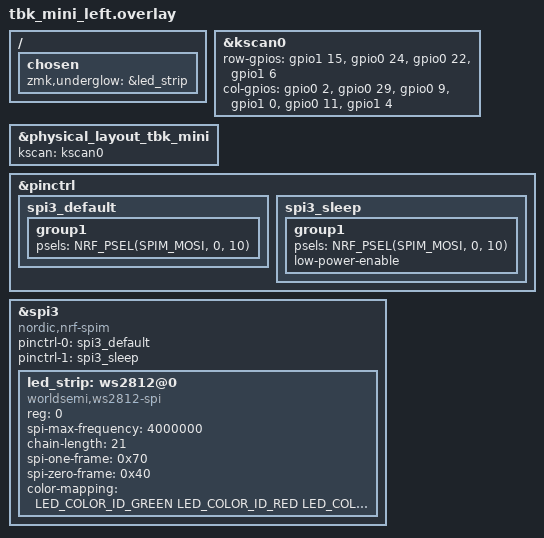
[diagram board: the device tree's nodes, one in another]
#include "tbk_mini.dtsi"
#include <dt-bindings/led/led.h>

&kscan0 {
    
    row-gpios
        = <&gpio1 15 GPIO_ACTIVE_HIGH>
        , <&gpio0 24 GPIO_ACTIVE_HIGH>
        , <&gpio0 22 GPIO_ACTIVE_HIGH>
        , <&gpio1 6 GPIO_ACTIVE_HIGH>
        ;

    col-gpios
        = <&gpio0 2 (GPIO_ACTIVE_HIGH | GPIO_PULL_DOWN)>
        , <&gpio0 29 (GPIO_ACTIVE_HIGH | GPIO_PULL_DOWN)>
        , <&gpio0 9 (GPIO_ACTIVE_HIGH | GPIO_PULL_DOWN)>
        , <&gpio1 0 (GPIO_ACTIVE_HIGH | GPIO_PULL_DOWN)>
        , <&gpio0 11 (GPIO_ACTIVE_HIGH | GPIO_PULL_DOWN)>
        , <&gpio1 4 (GPIO_ACTIVE_HIGH | GPIO_PULL_DOWN)>
        ;
};

&physical_layout_tbk_mini {
    kscan = <&kscan0>;
};

// --- RGB underglow (moved from boards/tbk_mini_left/nice_nano_v2.overlay) ---
// pin control for spi3 - MOSI on D16 (P0.10)
&pinctrl {
    spi3_default: spi3_default {
        group1 {
            psels = <NRF_PSEL(SPIM_MOSI, 0, 10)>;
        };
    };
    spi3_sleep: spi3_sleep {
        group1 {
            psels = <NRF_PSEL(SPIM_MOSI, 0, 10)>;
            low-power-enable;
        };
    };
};

&spi3 {
    compatible = "nordic,nrf-spim";
    status = "okay";
    pinctrl-0 = <&spi3_default>;
    pinctrl-1 = <&spi3_sleep>;
    pinctrl-names = "default", "sleep";

    led_strip: ws2812@0 {
        compatible = "worldsemi,ws2812-spi";
        reg = <0>;
        spi-max-frequency = <4000000>;

        chain-length = <21>;
        spi-one-frame = <0x70>;
        spi-zero-frame = <0x40>;
        color-mapping = <LED_COLOR_ID_GREEN
                         LED_COLOR_ID_RED
                         LED_COLOR_ID_BLUE>;
    };
};

/ {
    chosen {
        zmk,underglow = &led_strip;
    };
};
